# iostm32f105xx register map
Registers are 32-bit, access not given, no defined reset value unless marked. A register's access mark holds for its fields unless they carry their own. Addresses are absolute; registers are grouped by the start of their names; [hi:lo] are bit positions; {n}, {i} and the like mark numbered series.

## GPIOD
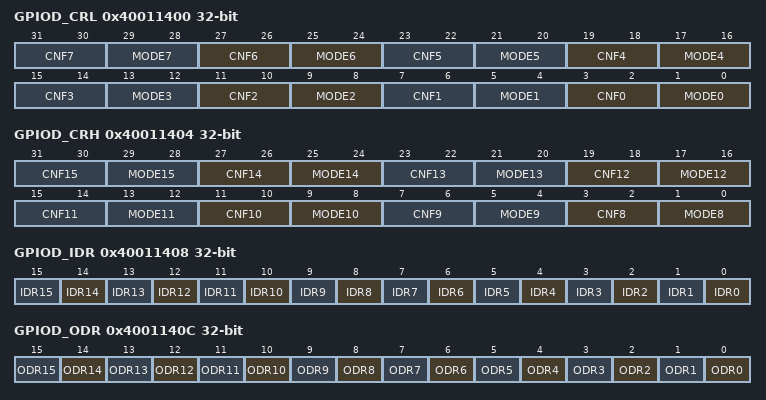
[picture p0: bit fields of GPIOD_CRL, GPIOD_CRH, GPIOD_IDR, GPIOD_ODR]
0x40011400 GPIOD_CRL
  [4n+3:4n+2] CNF{n} (n=0..7), [4n+1:4n] MODE{n} (n=0..7)
0x40011404 GPIOD_CRH
  [4n-29:4n-30] CNF{n} (n=8..15), [4n-31:4n-32] MODE{n} (n=8..15)
0x40011408 GPIOD_IDR
  [n] IDR{n} (n=0..15)
0x4001140C GPIOD_ODR
  [n] ODR{n} (n=0..15)
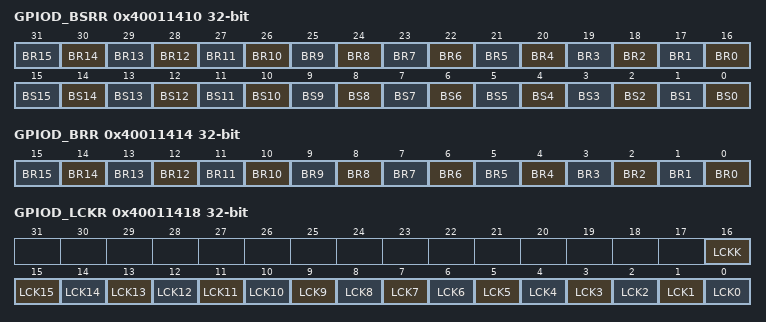
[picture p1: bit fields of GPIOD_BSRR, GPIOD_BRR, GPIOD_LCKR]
0x40011410 GPIOD_BSRR
  [n+16] BR{n} (n=0..15), [n] BS{n} (n=0..15)
0x40011414 GPIOD_BRR
  [n] BR{n} (n=0..15)
0x40011418 GPIOD_LCKR
  [16] LCKK, [n] LCK{n} (n=0..15)

## GPIOE
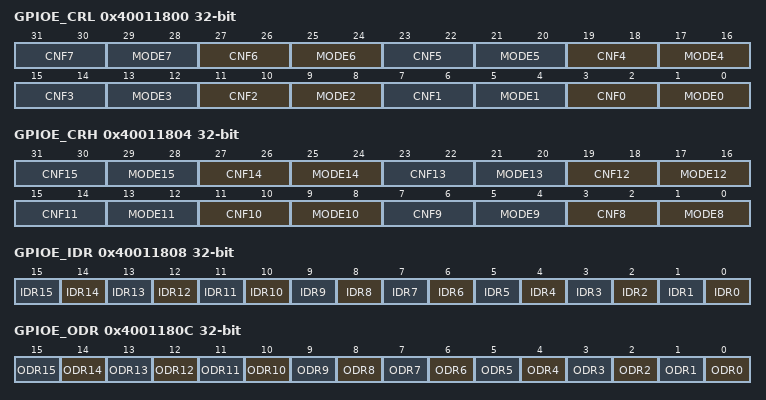
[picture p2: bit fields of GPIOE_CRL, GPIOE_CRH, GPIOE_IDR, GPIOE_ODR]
0x40011800 GPIOE_CRL
  [4n+3:4n+2] CNF{n} (n=0..7), [4n+1:4n] MODE{n} (n=0..7)
0x40011804 GPIOE_CRH
  [4n-29:4n-30] CNF{n} (n=8..15), [4n-31:4n-32] MODE{n} (n=8..15)
0x40011808 GPIOE_IDR
  [n] IDR{n} (n=0..15)
0x4001180C GPIOE_ODR
  [n] ODR{n} (n=0..15)
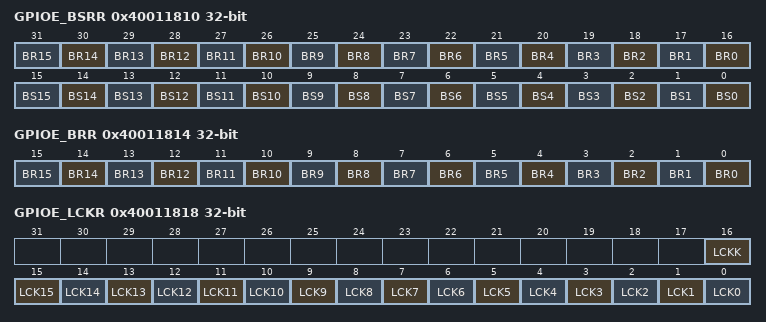
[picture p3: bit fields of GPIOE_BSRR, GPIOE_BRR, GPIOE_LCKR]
0x40011810 GPIOE_BSRR
  [n+16] BR{n} (n=0..15), [n] BS{n} (n=0..15)
0x40011814 GPIOE_BRR
  [n] BR{n} (n=0..15)
0x40011818 GPIOE_LCKR
  [16] LCKK, [n] LCK{n} (n=0..15)

## AFIO
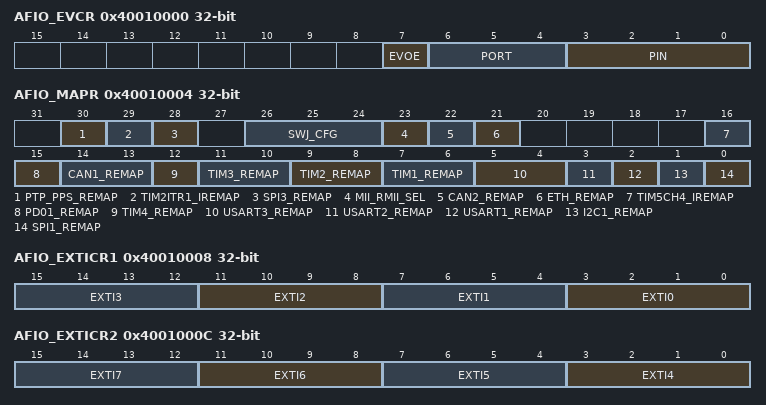
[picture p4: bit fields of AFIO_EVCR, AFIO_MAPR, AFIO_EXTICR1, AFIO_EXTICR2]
0x40010000 AFIO_EVCR
  [7] EVOE, [6:4] PORT, [3:0] PIN
0x40010004 AFIO_MAPR
  [30] PTP_PPS_REMAP, [29] TIM2ITR1_IREMAP, [28] SPI3_REMAP, [26:24] SWJ_CFG, [23] MII_RMII_SEL, [22] CAN2_REMAP, [21] ETH_REMAP, [16] TIM5CH4_IREMAP, [15] PD01_REMAP, [14:13] CAN1_REMAP, [12] TIM4_REMAP, [11:10] TIM3_REMAP, [9:8] TIM2_REMAP, [7:6] TIM1_REMAP, [5:4] USART3_REMAP, [3] USART2_REMAP, [2] USART1_REMAP, [1] I2C1_REMAP, [0] SPI1_REMAP
0x40010008 AFIO_EXTICR1
  [4n+3:4n] EXTI{n} (n=0..3)
0x4001000C AFIO_EXTICR2
  [4n-13:4n-16] EXTI{n} (n=4..7)
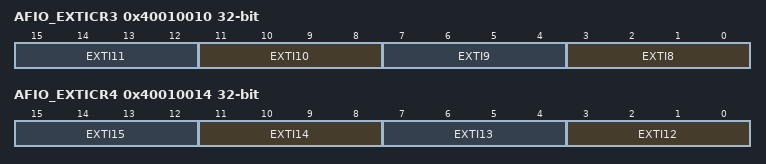
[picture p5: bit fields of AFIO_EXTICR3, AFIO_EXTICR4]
0x40010010 AFIO_EXTICR3
  [4n-29:4n-32] EXTI{n} (n=8..11)
0x40010014 AFIO_EXTICR4
  [4n-45:4n-48] EXTI{n} (n=12..15)

## EXTI
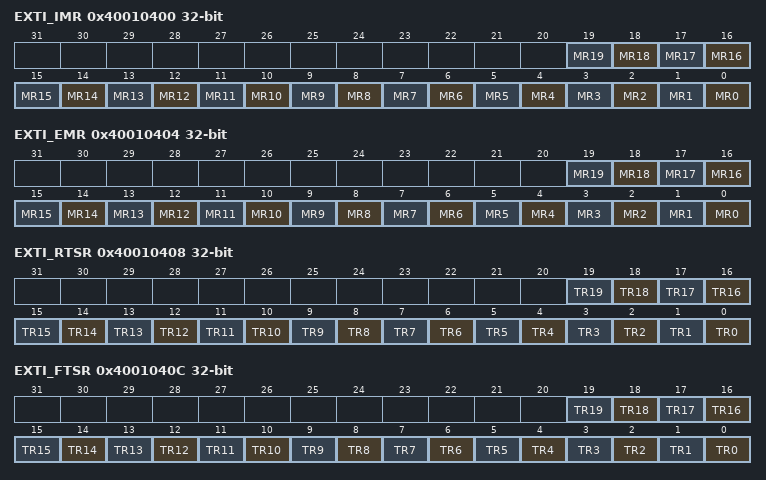
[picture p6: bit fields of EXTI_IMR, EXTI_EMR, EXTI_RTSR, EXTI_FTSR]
0x40010400 EXTI_IMR
  [n] MR{n} (n=0..19)
0x40010404 EXTI_EMR
  [n] MR{n} (n=0..19)
0x40010408 EXTI_RTSR
  [n] TR{n} (n=0..19)
0x4001040C EXTI_FTSR
  [n] TR{n} (n=0..19)
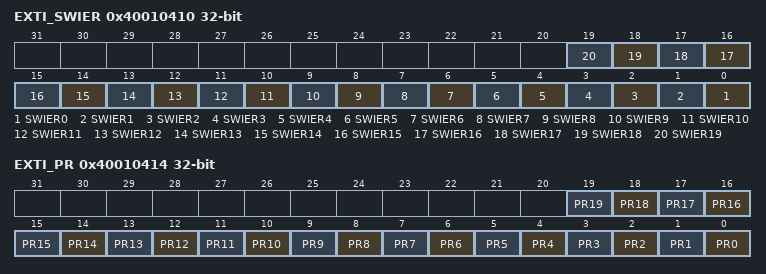
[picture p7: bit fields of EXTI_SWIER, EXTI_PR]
0x40010410 EXTI_SWIER
  [n] SWIER{n} (n=0..19)
0x40010414 EXTI_PR
  [n] PR{n} (n=0..19)

## DMA
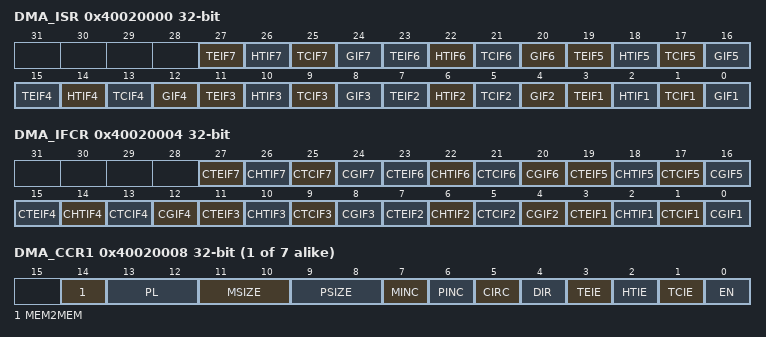
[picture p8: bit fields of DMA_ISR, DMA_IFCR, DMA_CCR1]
0x40020000 DMA_ISR
  [4n-1] TEIF{n} (n=1..7), [4n-2] HTIF{n} (n=1..7), [4n-3] TCIF{n} (n=1..7), [4n-4] GIF{n} (n=1..7)
0x40020004 DMA_IFCR
  [4n-1] CTEIF{n} (n=1..7), [4n-2] CHTIF{n} (n=1..7), [4n-3] CTCIF{n} (n=1..7), [4n-4] CGIF{n} (n=1..7)
{0x4001FFF4+0x14*i} DMA_CCR{i} (i=1..7)
  [14] MEM2MEM, [13:12] PL, [11:10] MSIZE, [9:8] PSIZE, [7] MINC, [6] PINC, [5] CIRC, [4] DIR, [3] TEIE, [2] HTIE, [1] TCIE, [0] EN
{0x4001FFF8+0x14*i} DMA_CNDTR{i} (i=1..7)
  [15:0] NDT
{0x4001FFFC+0x14*i} DMA_CPAR{i} (i=1..7)
{0x40020000+0x14*i} DMA_CMAR{i} (i=1..7)

## DMA2
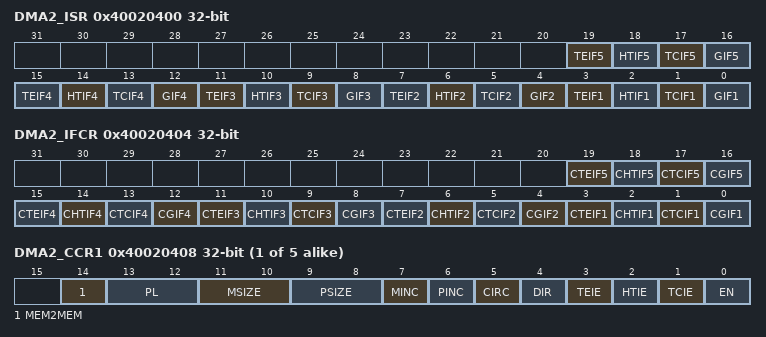
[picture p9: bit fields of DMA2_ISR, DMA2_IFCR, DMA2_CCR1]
0x40020400 DMA2_ISR
  [4n-1] TEIF{n} (n=1..5), [4n-2] HTIF{n} (n=1..5), [4n-3] TCIF{n} (n=1..5), [4n-4] GIF{n} (n=1..5)
0x40020404 DMA2_IFCR
  [4n-1] CTEIF{n} (n=1..5), [4n-2] CHTIF{n} (n=1..5), [4n-3] CTCIF{n} (n=1..5), [4n-4] CGIF{n} (n=1..5)
{0x400203F4+0x14*i} DMA2_CCR{i} (i=1..5)
  [14] MEM2MEM, [13:12] PL, [11:10] MSIZE, [9:8] PSIZE, [7] MINC, [6] PINC, [5] CIRC, [4] DIR, [3] TEIE, [2] HTIE, [1] TCIE, [0] EN
{0x400203F8+0x14*i} DMA2_CNDTR{i} (i=1..5)
  [15:0] NDT
{0x400203FC+0x14*i} DMA2_CPAR{i} (i=1..5)
{0x40020400+0x14*i} DMA2_CMAR{i} (i=1..5)

## RTC
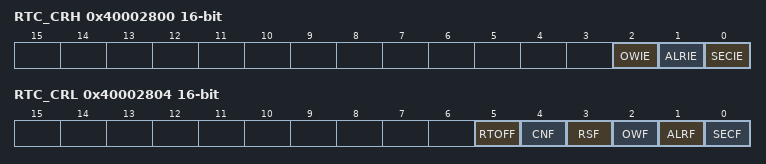
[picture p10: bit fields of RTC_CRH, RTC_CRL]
0x40002800 RTC_CRH 16-bit
  [2] OWIE, [1] ALRIE, [0] SECIE
0x40002804 RTC_CRL 16-bit
  [5] RTOFF, [4] CNF, [3] RSF, [2] OWF, [1] ALRF, [0] SECF
0x40002808 RTC_PRLH 16-bit
  [3:0] PRL
0x4000280C RTC_PRLL 16-bit
0x40002810 RTC_DIVH 16-bit
  [3:0] RTC_DIV
0x40002814 RTC_DIVL 16-bit
0x40002818 RTC_CNTH 16-bit
0x4000281C RTC_CNTL 16-bit
0x40002820 RTC_ALRH 16-bit
0x40002824 RTC_ALRL 16-bit

## BKP
{0x40006C00+4i} BKP_DR{i} 16-bit (i=1..10)
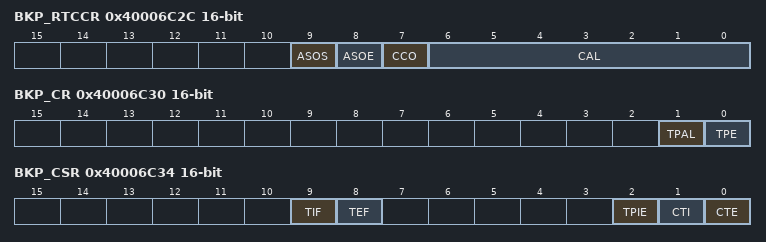
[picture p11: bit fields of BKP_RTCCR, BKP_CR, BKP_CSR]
0x40006C2C BKP_RTCCR 16-bit
  [9] ASOS, [8] ASOE, [7] CCO, [6:0] CAL
0x40006C30 BKP_CR 16-bit
  [1] TPAL, [0] TPE
0x40006C34 BKP_CSR 16-bit
  [9] TIF, [8] TEF, [2] TPIE, [1] CTI, [0] CTE
{0x40006C14+4i} BKP_DR{i} 16-bit (i=11..42)
